# Template register map
Vendor: VendorName Co.Ltd; Series: SeriesName; File version: 1.2
CPU: CM7 r0p1, little endian, MPU, FPU, 4 interrupt priority bits
Registers are 32-bit, read-write, no defined reset value unless marked. A register's access mark holds for its fields unless they carry their own. Offsets are from the block's base; [hi:lo] are bit positions; lines under a group give offsets from that group; {n}, {i} and the like mark numbered series.

## CAN1 — Controller Area Network 1
Base 0x40088000
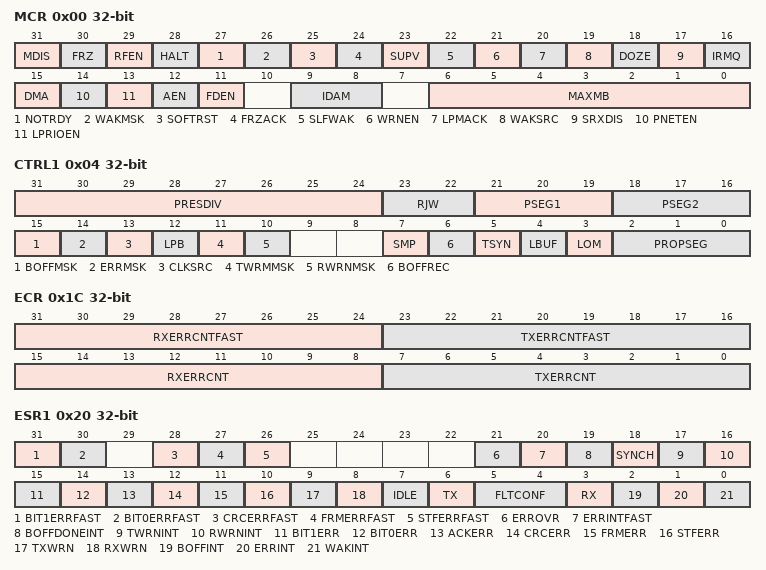
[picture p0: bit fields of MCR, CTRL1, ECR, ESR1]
0x00 MCR — CAN module config register
  [31] MDIS — CAN MDIS bit: module disable
  [30] FRZ — CAN FRZ bit: freeze enable
  [29] RFEN — CAN RFEN bit: Rx FIFO enable
  [28] HALT — CAN HALT bit: halt FlexCAN
  [27] NOTRDY — CAN NOTRDY bit: FlexCAN not ready
  [26] WAKMSK — CAN WAKMSK bit: wake up interrupt mask
  [25] SOFTRST — CAN SOFTRST bit: soft reset
  [24] FRZACK ro — CAN FRZACK bit: freeze mode acknowledge
  [23] SUPV — CAN SUPV bit: supervisor mode
  [22] SLFWAK — CAN SLFWAK bit: self wake up
  [21] WRNEN — CAN WRNEN bit: warning interrupt enable
  [20] LPMACK — CAN LPMACK bit: low-power mode acknowledge
  [19] WAKSRC — CAN WAKSRC bit: wake up source
  [18] DOZE — CAN DOZE bit: doze mode enable
  [17] SRXDIS — CAN SRXDIS bit: self reception disable
  [16] IRMQ — CAN IRMQ bit: individual Rx masking And queue enable
  [15] DMA — CAN DMA bit: DMA enable
  [14] PNETEN — CAN PNETEN bit: pretended networking enable
  [13] LPRIOEN — CAN LPRIOEN bit: local priority enable
  [12] AEN — CAN AEN bit: abort enable
  [11] FDEN — CAN FDEN bit: CAN FD operation enable
  [9:8] IDAM — CAN IDAM[1:0] bit: ID acceptance mode
  [6:0] MAXMB — CAN MAXMB[6:0] bit: number of the last message buffer
0x04 CTRL1 — CAN control register 1
  [31:24] PRESDIV — CAN PRESDIV[7:0] bit: prescaler division factor
  [23:22] RJW — CAN RJW[1:0] bit: resync jump width
  [21:19] PSEG1 — CAN PSEG1[2:0] bit: phase segment 1
  [18:16] PSEG2 — CAN PSEG2[2:0] bit: phase segment 2
  [15] BOFFMSK — CAN BOFFMSK bit: bus off interrtupt mask
  [14] ERRMSK — CAN ERRMSK bit: error interrupt mask
  [13] CLKSRC — CAN CLKSRC bit: CAN engine clock source
  [12] LPB — CAN LPB bit: loop-back mode
  [11] TWRMMSK — CAN TWRMMSK bit: Tx warning inrerrupt mask
  [10] RWRNMSK — CAN RWRNMSK bit: Rx warn inrerrupt mask
  [7] SMP — CAN SMP bit: CAN bit sampling
  [6] BOFFREC — CAN BOFFREC bit: bus off recovery
  [5] TSYN — CAN TSYN bit: timer sync
  [4] LBUF — CAN LBUF bit: lowest buffer transmitted first
  [3] LOM — CAN LOM bit: listen-only mode
  [2:0] PROPSEG — CAN PROPSEG[2:0] bit: propagation segment
0x08 TIMER — CAN free-running timer register
  [15:0] TIMER — CAN TIMER[15:0] bit: timer value
0x10 RXMGMASK — CAN receiving mailbox global mask register
  [31:0] MG — CAN MG[31:0] bit: Rx mailboxes global mask bits
0x14 RX14MASK — CAN receiving buffer 14 mask register
  [31:0] RX14M — CAN RX14M[31:0] bit: Rx buffer 14 mask bits
0x18 RX15MASK — CAN receiving buffer 15 mask register
  [31:0] RX15M — CAN RX15M[31:0] bit: Rx buffer 15 mask bits
0x1C ECR — CAN error count register
  [31:24] RXERRCNTFAST ro — CAN RXERRCNTFAST[7:0] bit: receive error counter for fast bits
  [23:16] TXERRCNTFAST ro — CAN TXERRCNTFAST[7:0] bit: transmit error counter for fast bits
  [15:8] RXERRCNT — CAN RXERRCNT[7:0] bit: receive error counter
  [7:0] TXERRCNT — CAN TXERRCNT[7:0] bit: transmit error counter
0x20 ESR1 — CAN error and state register 1
  [31] BIT1ERRFAST ro — CAN BIT1ERRFAST bit: bit1 error in the data phase of CAN FD frames with the BRS bit set
  [30] BIT0ERRFAST ro — CAN BIT0ERRFAST bit: bit0 error in the data phase of CAN FD frames with the BRS bit set
  [28] CRCERRFAST ro — CAN CRCERRFAST bit: cyclic redundancy check error in the CRC field of CAN FD frames with the BRS bit set
  [27] FRMERRFAST ro — CAN FRMERRFAST bit: form error in the data phase of CAN FD frames with the BRS bit set
  [26] STFERRFAST ro — CAN STFERRFAST bit: stuffing error in the data phase of CAN FD frames with the BRS bit set
  [21] ERROVR — CAN ERROVR bit: error overflow
  [20] ERRINTFAST — CAN ERRINTFAST bit: error interrupt for errors detected in the data phase of CAN FD frames with the BRS bit set
  [19] BOFFDONEINT — CAN BOFFDONEINT bit: bus off done interrupt
  [18] SYNCH — CAN SYNCH bit: CAN synchronization status
  [17] TWRNINT — CAN TWRNINT bit: Tx warning interrupt flag
  [16] RWRNINT — CAN RWRNINT bit: Rx warning interrupt flag
  [15] BIT1ERR ro — CAN BIT1ERR bit: bit1 error
  [14] BIT0ERR ro — CAN BIT0ERR bit: bit0 error
  [13] ACKERR ro — CAN ACKERR bit: acknowledge error
  [12] CRCERR ro — CAN CRCERR bit: cyclic redundancy check error
  [11] FRMERR ro — CAN FRMERR bit: form error
  [10] STFERR ro — CAN STFERR bit: stuffing error
  [9] TXWRN ro — CAN TXWRN bit: Tx error warning
  [8] RXWRN ro — CAN RXWRN bit: Rx error warning
  [7] IDLE ro — CAN IDLE bit: idle state bit
  [6] TX ro — CAN TX bit: FlexCAN in transmission
  [5:4] FLTCONF ro — CAN FLTCONF[1:0] bit: fault confinement state
  [3] RX ro — CAN RX bit: FlexCAN in reception
  [2] BOFFINT — CAN BOFFINT bit: bus off interrupt
  [1] ERRINT — CAN ERRINT bit: error interrupt
  [0] WAKINT — CAN WAKINT bit: wake up interrupt
0x28 IMASK1 — CAN interrupt mask register 1
  [31:0] BUF31TO0M — CAN BUF31TO0M[31:0] bit: buffer MBi mask
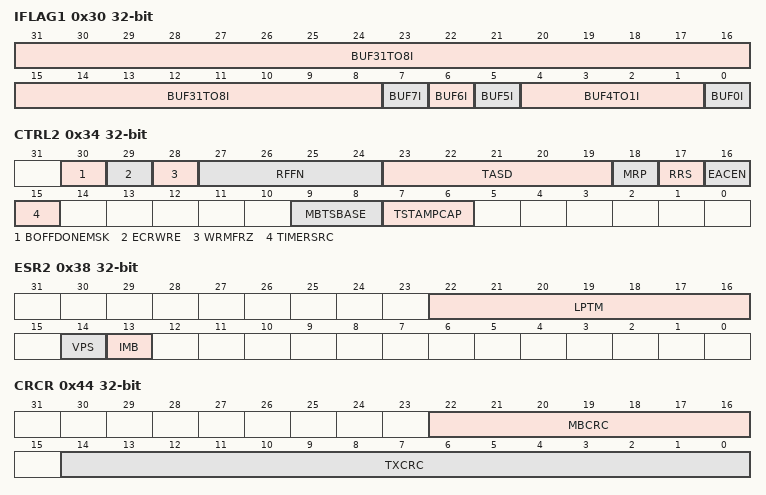
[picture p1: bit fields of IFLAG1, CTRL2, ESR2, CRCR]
0x30 IFLAG1 — CAN interrupt flag register 1
  [31:8] BUF31TO8I — CAN BUF31TO8I[23:0] bit: buffer MBi interrupt
  [7] BUF7I — CAN BUF7I bit: buffer MB7 interrupt or legacy Rx FIFO overflow
  [6] BUF6I — CAN BUF6I bit: buffer MB6 interrupt or legacy Rx FIFO warning
  [5] BUF5I — CAN BUF5I bit: buffer MB5 interrupt or frames available in legacy Rx FIFO
  [4:1] BUF4TO1I — CAN BUF4TO1I[3:0] bit: buffer MBi interrupt or reserved
  [0] BUF0I — CAN BUF0I bit: buffer MB0 interrupt or clear legacy Rx FIFO bit
0x34 CTRL2 — CAN control register 2
  [30] BOFFDONEMSK — CAN BOFFDONEMSK bit: bus off done interrupt mask
  [29] ECRWRE — CAN ECRWRE bit: error-correction configuration register write enable
  [28] WRMFRZ — CAN WRMFRZ bit: writing-access to memory in freeze mode
  [27:24] RFFN — CAN RFFN[3:0] bit: number of legacy Rx FIFO filters
  [23:19] TASD — CAN TASD[4:0] bit: Tx arbitration start delay
  [18] MRP — CAN MRP bit: mailboxes reception priority
  [17] RRS — CAN RRS bit: remote request storing
  [16] EACEN — CAN EACEN bit: entire frame arbitration field comparison enable for Rx mailboxes
  [15] TIMERSRC — CAN TIMERSRC bit: timer source
  [9:8] MBTSBASE — CAN MBTSBASE[1:0] bit: message buffer time stamp base
  [7:6] TSTAMPCAP — CAN TSTAMPCAP[1:0] bit: time stamp capture point
0x38 ESR2 ro — CAN error and state register 2
  [22:16] LPTM — CAN LPTM[6:0] bit: lowest priority Tx mailbox
  [14] VPS — CAN VPS bit: valid priority status
  [13] IMB — CAN IMB bit: inactive mailbox
0x44 CRCR ro — CAN CRC register
  [22:16] MBCRC — CAN MBCRC[6:0] bit: CRC mailbox
  [14:0] TXCRC — CAN TXCRC[14:0] bit: transmitted CRC value
0x48 RXFGMASK — CAN receiving FIFO mailbox global mask register
  [31:0] FGM — CAN FGM[31:0] bit: Rx FIFO global mask bits
0x4C RXFIR ro — CAN receiving FIFO information register
  [8:0] IDHIT — CAN IDHIT[8:0] bit: identifier acceptance filter hit indicator
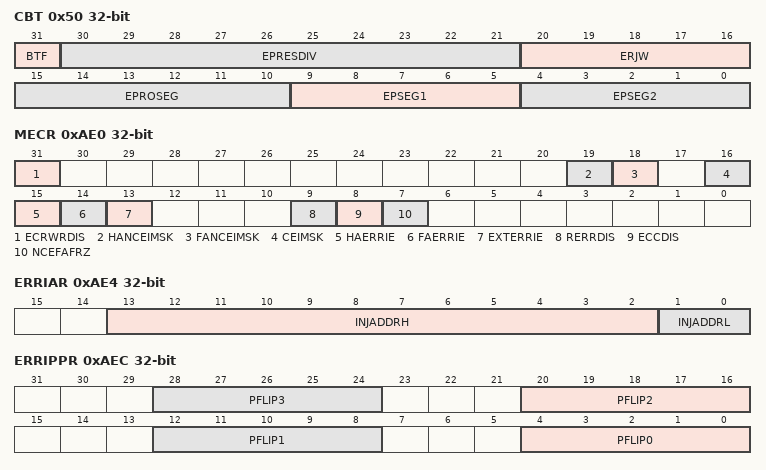
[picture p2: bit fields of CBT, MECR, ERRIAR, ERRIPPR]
0x50 CBT — CAN bits timer register
  [31] BTF — CAN BTF bit: bit timing format enable
  [30:21] EPRESDIV — CAN EPRESDIV[9:0] bit: extended prescaler division factor
  [20:16] ERJW — CAN ERJW[4:0] bit: extended resync jump width
  [15:10] EPROSEG — CAN EPROSEG[5:0] bit: extended propagation segment
  [9:5] EPSEG1 — CAN EPSEG1[4:0] bit: extended phase segment 1
  [4:0] EPSEG2 — CAN EPSEG2[4:0] bit: extended phase segment 2
0x7C GFWR — CAN glitch filter window register
  [7:0] GFWR — CAN GFWR[7:0] bit: fault filter width
{0x880+4i} RXIMRX[{i}] (i=0..31) — Grouping of RXIMR0~RXIMR31
  [31:0] MI — CAN MI[31:0] bit: individual mask bit x
0xAE0 MECR — CAN memory error control register
  [31] ECRWRDIS — CAN ECRWRDIS bit: error configuration register write disable
  [19] HANCEIMSK — CAN HANCEIMSK bit: host access with non-correctable errors interrupt mask
  [18] FANCEIMSK — CAN FANCEIMSK bit: FlexCAN access with non-correctable errors interrupt mask
  [16] CEIMSK — CAN CEIMSK bit: correctable errors interrupt mask
  [15] HAERRIE — CAN HAERRIE bit: host access error injection enable
  [14] FAERRIE — CAN FAERRIE bit: FlexCAN access error injection enable
  [13] EXTERRIE — CAN EXTERRIE bit: extended error injection enable
  [9] RERRDIS — CAN RERRDIS bit: error report disable
  [8] ECCDIS — CAN ECCDIS bit: error correction disable
  [7] NCEFAFRZ — CAN NCEFAFRZ bit: non-correctable errors in FlexCAN access put device in freeze mode
0xAE4 ERRIAR — CAN input address error register
  [13:2] INJADDRH — CAN INJADDRH[11:0] bit: error injection address high
  [1:0] INJADDRL ro — CAN INJADDRL[1:0] bit: error injection address low
0xAE8 ERRIDPR — CAN input data error register
  [31:0] DFLIP — CAN DFLIP[31:0] bit: data flip pattern
0xAEC ERRIPPR — CAN input parity check error register
  [8n+4:8n] PFLIP{n} (n=0..3) — CAN PFLIP{n}[4:0] bit: parity flip pattern for byte {n}
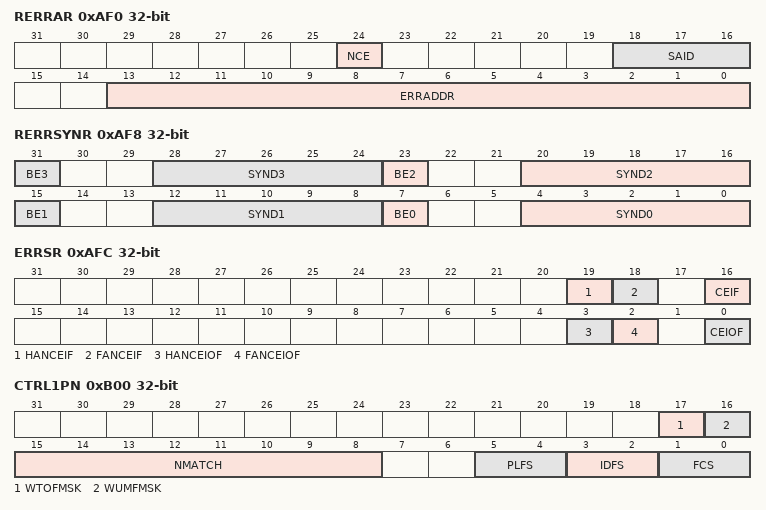
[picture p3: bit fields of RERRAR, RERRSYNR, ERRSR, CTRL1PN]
0xAF0 RERRAR ro — CAN report error address register
  [24] NCE — CAN NCE bit: non-correctable error
  [18:16] SAID — CAN SAID[2:0] bit: SAID mode enable
  [13:0] ERRADDR — CAN ERRADDR[13:0] bit: address where the error was detected
0xAF4 RERRDR ro — CAN report error data register
  [31:0] RDATA — CAN RDATA[31:0] bit: raw data word read from memory with error
0xAF8 RERRSYNR ro — CAN report error synthesis register
  [8n+7] BE{n} (n=0..3) — CAN BE{n} bit: byte enabled for byte {n}
  [8n+4:8n] SYND{n} (n=0..3) — CAN SYND{n}[4:0] bit: error syndrome for byte {n}
0xAFC ERRSR — CAN error state register
  [19] HANCEIF — CAN HANCEIF bit: host access with non-correctable error interrupt flag
  [18] FANCEIF — CAN FANCEIF bit: FlexCAN access with non-correctable error interrupt flag
  [16] CEIF — CAN CEIF bit: correctable error interrupt flag
  [3] HANCEIOF — CAN HANCEIOF bit: host access with non-correctable error interrupt overrun flag
  [2] FANCEIOF — CAN FANCEIOF bit: FlexCAN access with non-correctable error interrupt overrun flag
  [0] CEIOF — CAN CEIOF bit: correctable error interrupt overrun flag
0xB00 CTRL1PN — CAN PN control register 1
  [17] WTOFMSK — CAN WTOFMSK bit: wake up by timeout flag mask bit
  [16] WUMFMSK — CAN WUMFMSK bit: wake up by match flag mask bit
  [15:8] NMATCH — CAN NMATCH[7:0] bit: match message number with same filtering conditions
  [5:4] PLFS — CAN PLFS[1:0] bit: payload filtering selection
  [3:2] IDFS — CAN IDFS[1:0] bit: ID filtering selection
  [1:0] FCS — CAN FCS[1:0] bit: filtering combination selection
0xB04 CTRL2PN — CAN PN control register 2
  [15:0] MATCHTO — CAN MATCHTO[15:0] bit: match and define a timeout value
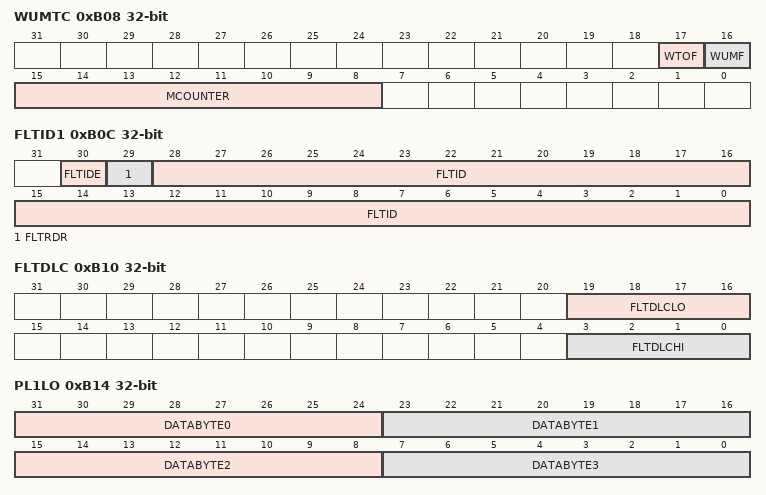
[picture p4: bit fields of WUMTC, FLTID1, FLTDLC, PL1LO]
0xB08 WUMTC — CAN PN wakeup and match register
  [17] WTOF — CAN WTOF bit: wake up by timeout flag bit
  [16] WUMF — CAN WUMF bit: wake up by match flag bit
  [15:8] MCOUNTER ro — CAN MCOUNTER[7:0] bit: number of matches while in pretended networking
0xB0C FLTID1 — CAN PN ID filter register
  [30] FLTIDE — CAN FLTIDE bit: ID extended filter
  [29] FLTRDR — CAN FLTRDR bit: remote transmission request filter
  [28:0] FLTID — CAN FLTID[28:0] bit: ID filter 1 for pretended networking filtering
0xB10 FLTDLC — CAN PN DLC filter register
  [19:16] FLTDLCLO — CAN FLTDLCLO[3:0] bit: lower limit for length of data bytes filter
  [3:0] FLTDLCHI — CAN FLTDLCHI[3:0] bit: upper limit for length of data bytes filter
0xB14 PL1LO — CAN PN PAYLOAD low filter register
  [31-8n:24-8n] DATABYTE{n} (n=0..3) — CAN DATABYTE{n}[7:0] bit: payload filter 1 low order bits {n}
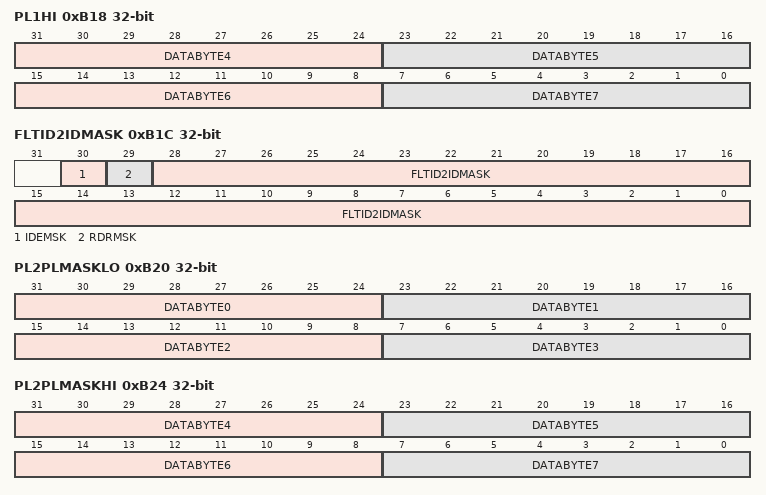
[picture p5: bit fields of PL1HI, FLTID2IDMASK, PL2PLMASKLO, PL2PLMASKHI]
0xB18 PL1HI — CAN PN PAYLOAD high filter register
  [63-8n:56-8n] DATABYTE{n} (n=4..7) — CAN DATABYTE{n}[7:0] bit: payload filter 1 low order bits {n}
0xB1C FLTID2IDMASK — CAN PN ID filter mask register
  [30] IDEMSK — CAN IDEMSK bit: ID extended mask bit
  [29] RDRMSK — CAN RDRMSK bit: remote transmission request mask bit
  [28:0] FLTID2IDMASK — CAN FLTID2IDMASK[28:0] bit: ID filter 2 pretended networking filtering
0xB20 PL2PLMASKLO — CAN PN PAYLOAD low filter mask register
  [31-8n:24-8n] DATABYTE{n} (n=0..3) — CAN DATABYTE{n}[7:0] bit: payload filter 2 low order bits {n}
0xB24 PL2PLMASKHI — CAN PN PAYLOAD high filter mask register
  [63-8n:56-8n] DATABYTE{n} (n=4..7) — CAN DATABYTE{n}[7:0] bit: payload filter 2 low order bits {n}
{0xB40+0x10*i} WMBX[{i}] (i=0..3) group — Grouping of WMB0CS/ID/D03/D47~WMB3CS/ID/D03/D47
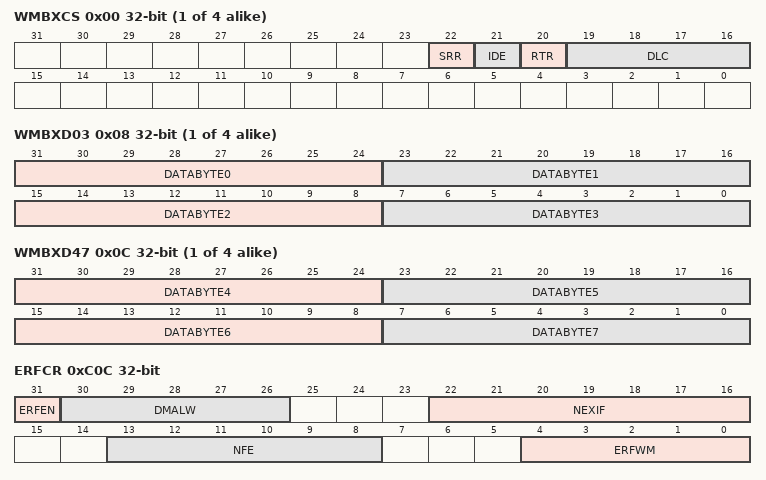
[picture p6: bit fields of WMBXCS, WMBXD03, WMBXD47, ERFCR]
  0x00 WMBXCS ro — CAN wakeup message buffer x CS register
    [22] SRR — CAN SRR bit: substitute remote request x
    [21] IDE — CAN IDE bit: ID extended bit x
    [20] RTR — CAN RTR bit: remote transmission request bit x
    [19:16] DLC — CAN DLC[3:0] bit: length of data in bytes x
  0x04 WMBXID ro — CAN wakeup message buffer x ID register
    [28:0] ID — CAN ID[28:0] bit: received ID under pretended networking mode x
  0x08 WMBXD03 ro — CAN wakeup message buffer x DATA0~3 register
    [31-8n:24-8n] DATABYTE{n} (n=0..3) — CAN DATABYTE{n}[7:0] bit: receive payload corresponding to data byte {n} x
  0x0C WMBXD47 ro — CAN wakeup message buffer x DATA4~7 register
    [63-8n:56-8n] DATABYTE{n} (n=4..7) — CAN DATABYTE{n}[7:0] bit: receive payload corresponding to data byte {n} x
0xC0C ERFCR — CAN enhanced receiving FIFO control register
  [31] ERFEN — CAN ERFEN bit: enhanced Rx FIFO enable
  [30:26] DMALW — CAN DMALW[4:0] bit: DMA last word
  [22:16] NEXIF — CAN NEXIF[6:0] bit: number of extended ID filter elements
  [13:8] NFE — CAN NFE[5:0] bit: number of enhanced Rx FIFO filter elements
  [4:0] ERFWM — CAN ERFWM[4:0] bit: enhanced Rx FIFO watermark
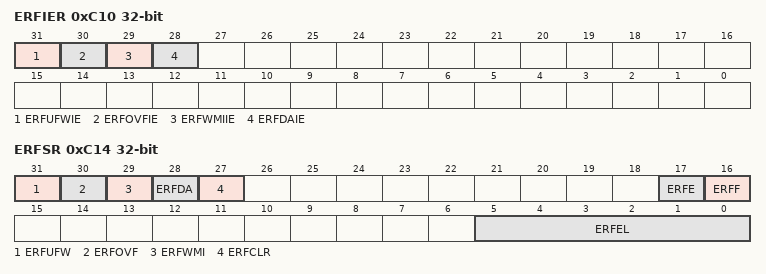
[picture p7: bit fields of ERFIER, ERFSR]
0xC10 ERFIER — CAN enhanced receiving FIFO interrupt enable register
  [31] ERFUFWIE — CAN ERFUFWIE bit: enhanced Rx FIFO underflow interrupt enable
  [30] ERFOVFIE — CAN ERFOVFIE bit: enhanced Rx FIFO overflow interrupt enable
  [29] ERFWMIIE — CAN ERFWMIIE bit: enhanced Rx FIFO watermark indication interrupt enable
  [28] ERFDAIE — CAN ERFDAIE bit: enhanced Rx FIFO data available interrupt enable
0xC14 ERFSR — CAN enhanced receiving FIFO state register
  [31] ERFUFW — CAN ERFUFW bit: enhanced Rx FIFO underflow
  [30] ERFOVF — CAN ERFOVF bit: enhanced Rx FIFO overflow
  [29] ERFWMI — CAN ERFWMI bit: enhanced Rx FIFO watermark indication
  [28] ERFDA — CAN ERFDA bit: enhanced Rx FIFO data available
  [27] ERFCLR wo — CAN ERFCLR bit: enhanced Rx FIFO clear
  [17] ERFE ro — CAN ERFE bit: enhanced Rx FIFO empty
  [16] ERFF ro — CAN ERFF bit: enhanced Rx FIFO full
  [5:0] ERFEL ro — CAN ERFEL[5:0] bit: enhanced Rx FIFO elements
{0x3000+4i} ERFFELX[{i}] (i=0..31) — Grouping of ERFFEL0~ERFFEL31
  [31:0] FEL — CAN FEL[31:0] bit: filter element bits x
